# R7FA2A2AD register map
Vendor: Renesas Electronics Corporation; Series: RA2A2; File version: 1.20.02
CPU: CM23 r1p0, little endian, MPU, no FPU, VTOR, 2 interrupt priority bits, 32 interrupts
Registers are 8-bit, read-write, reset 0x0 unless marked. A register's access mark holds for its fields unless they carry their own. Offsets are from the block's base; [hi:lo] are bit positions; {n}, {i} and the like mark numbered series.

## SDADC24_B — 24-Bit Sigma-Delta A/D Converter B
Base 0x4009C000
0x00 SDADCCR — Sigma-Delta A/D Clock Control Register
  [1:0] CK — Operating clock of the digital block
    0=Disabled; 2=Set when SDADCCLK frequency is 12.0 MHz or 12.8 MHz; 3=Set when SDADCCLK frequency is 16.0 MHz; other=Others (Setting prohibited)
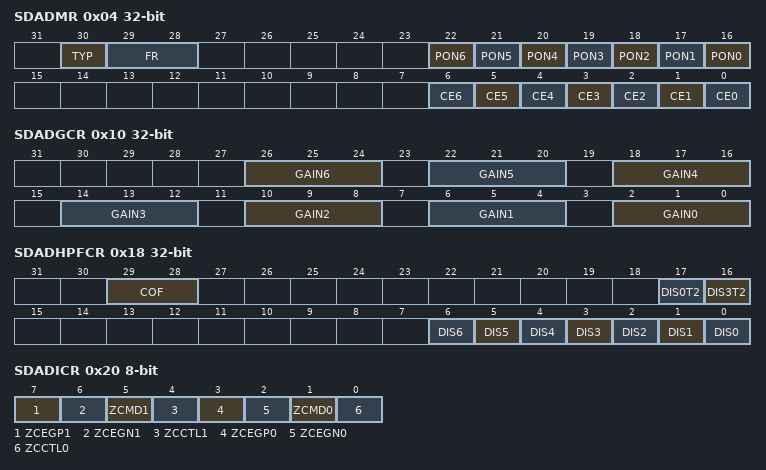
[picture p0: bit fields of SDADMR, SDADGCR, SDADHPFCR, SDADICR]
0x04 SDADMR 32-bit — Sigma-Delta A/D Mode Register
  [30] TYP — Resolution of A/D conversion result reading
    0=24-bit resolution; 1=16-bit resolution
  [29:28] FR — Sampling mode select
    0=4 kHz sampling mode; 1=8 kHz sampling mode; 2=8 kHz/4 kHz hybrid sampling mode; 3=Setting prohibited
  [n+16] PON{n} (n=0..6) — Sigma-Delta A/D converter power-on control for channel n
    0=Power off; 1=Power on
  [n] CE{n} (n=0..6) — Sigma-Delta A/D converter operation enable for channel n
    0=Electric charge reset; 1=Normal operation
0x0C SDADRR — Sigma-Delta A/D Reset Register
  [0] RES — Sigma-Delta A/D converter reset
    0=Normal operation; 1=Reset state
0x10 SDADGCR 32-bit — Sigma-Delta A/D Gain Control Register
  [all] fields
    0=1x; 1=2x; 2=4x; 3=8x; 4=16x; 5=32x; other=Others (Setting prohibited)
  [4n+2:4n] GAIN{n} (n=0..6) — Preamplifier gain for channel {n}
0x18 SDADHPFCR 32-bit — Sigma-Delta A/D HPF Control Register
  [29:28] COF — Cut-off frequency of HPF (see )
  [17] DIS0T2 — HPF bypass for channel m Type 2 output
    0=HPF enabled; 1=HPF disabled
  [16] DIS3T2 — HPF bypass for channel m Type 2 output
    0=HPF enabled; 1=HPF disabled
  [n] DIS{n} (n=0..6) — HPF bypass for channel n Type 1 output
    0=HPF enabled; 1=HPF disabled
0x20 SDADICR — Sigma-Delta A/D Interrupt Control Register
  [7] ZCEGP1 — Rising edge detection enable for Zero-cross detection 1
    0=Disabled; 1=Enabled
  [6] ZCEGN1 — Falling edge detection enable for zero-cross detection 1
    0=Disabled; 1=Enabled
  [5] ZCMD1 — Interrupt output mode for zero-cross detection 1
    0=Pulse output mode; 1=Level output mode
  [4] ZCCTL1 — Detection channel for zero-cross detection 1
    0=Channel 3; 1=Channel 0
  [3] ZCEGP0 — Rising edge detection enable for zero-cross detection 0
    0=Disabled; 1=Enabled
  [2] ZCEGN0 — Falling edge detection enable for zero-cross detection 0
    0=Disabled; 1=Enabled
  [1] ZCMD0 — Interrupt output mode for zero-cross detection 0
    0=Pulse output mode; 1=Level output mode
  [0] ZCCTL0 — Detection channel for zero-cross detection 0
    0=Channel 2; 1=Channel 1
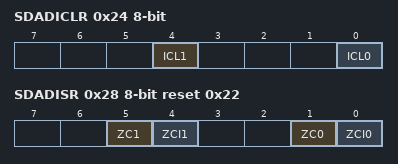
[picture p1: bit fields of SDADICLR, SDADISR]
0x24 SDADICLR — Sigma-Delta A/D Interrupt Clear Register
  [4] ICL1 wo — Zero-cross detection interrupt 1 clear
    0=No operation; 1=Clears zero-cross detection interrupt 1 (SDADC_ADZC1)
  [0] ICL0 wo — Zero-cross detection interrupt 0 clear
    0=No operation; 1=Clears zero-cross detection interrupt 0 (SDADC_ADZC0)
0x28 SDADISR reset 0x22 — Sigma-Delta A/D Interrupt Status Register
  [5] ZC1 ro — DF output status for Zero-cross detection 1
    0=DF output is negative; 1=DF output is positive
  [4] ZCI1 ro — Zero-cross detection interrupt status for zero-cross detection 1
    0=Zero-cross detection interrupt 1 (SDADC_ADZC1) signal is 0; 1=Zero-cross detection interrupt 1 (SDADC_ADZC1) signal is 1
  [1] ZC0 ro — DF output status for zero-cross detection 0
    0=DF output is negative; 1=DF output is positive
  [0] ZCI0 ro — Zero-cross detection interrupt status for zero-cross detection 0
    0=Zero-cross detection interrupt 0 (SDADC_ADZC0) signal is 0; 1=Zero-cross detection interrupt 0 (SDADC_ADZC0) signal is 1
{0x40+4i} SDADPHCR{i} (i=0..7) 16-bit — Sigma-Delta A/D Phase Control Register {i}
  [10:0] PH — Phase adjustment for channel n (n = 0 to 6)
{0x80+4i} SDADCR{i} (i=0..6) 32-bit ro — Sigma-Delta A/D Conversion Result Register {i} Type 1
  [31:0] SDADCR — A/D conversion result for channel n Type 1
{0xA0+4i} SDADCR{i}T2 (i=0..3) 32-bit ro — Sigma-Delta A/D Conversion Result Register {i} Type 2
  [31:0] SDADCR — A/D conversion result for channel m Type 2
{0xC0+4i} SDADCRLPF{i} (i=0..6) 32-bit ro — Sigma-Delta A/D Conversion Result Register (LPF) {i} Type 1
  [31:0] SDADCR — A/D conversion result for channel n LPF output Type 1
{0xE0+4i} SDADCRLPF{i}T2 (i=0..3) 32-bit ro — Sigma-Delta A/D Conversion Result Register (LPF) {i} Type 2
  [31:0] SDADCR — A/D conversion result for channel m LPF output Type 2
